# STM32G474xx register map
File version: 1.5
CPU: CM4 r0p1, little endian, MPU, FPU, 4 interrupt priority bits
Registers are 32-bit, read-write, reset 0x0 unless marked. A register's access mark holds for its fields unless they carry their own. Offsets are from the block's base; [hi:lo] are bit positions; lines under a group give offsets from that group; {n}, {i} and the like mark numbered series.

## ADC1 — Analog-to-Digital Converter
Base 0x50000000
Same registers: ADC2 0x50000100, ADC4 0x50000500
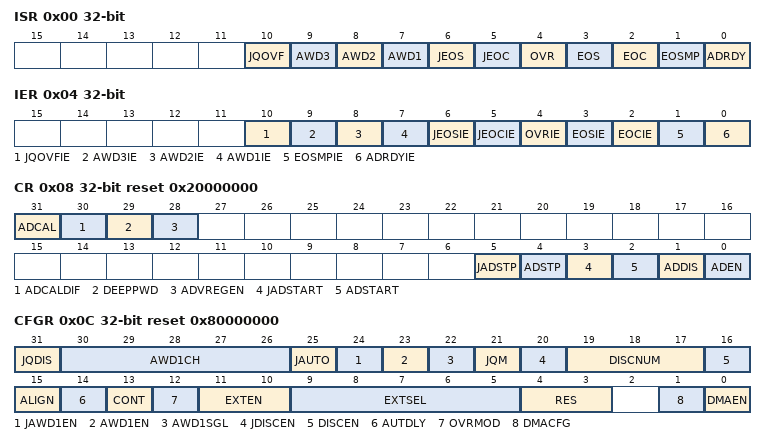
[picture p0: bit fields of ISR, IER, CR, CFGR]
0x00 ISR — interrupt and status register
  [10] JQOVF, [9] AWD3, [8] AWD2, [7] AWD1, [6] JEOS, [5] JEOC, [4] OVR, [3] EOS, [2] EOC, [1] EOSMP, [0] ADRDY
0x04 IER — interrupt enable register
  [10] JQOVFIE, [9] AWD3IE, [8] AWD2IE, [7] AWD1IE, [6] JEOSIE, [5] JEOCIE, [4] OVRIE, [3] EOSIE, [2] EOCIE, [1] EOSMPIE, [0] ADRDYIE
0x08 CR reset 0x20000000 — control register
  [31] ADCAL, [30] ADCALDIF, [29] DEEPPWD, [28] ADVREGEN, [5] JADSTP, [4] ADSTP, [3] JADSTART, [2] ADSTART, [1] ADDIS, [0] ADEN
0x0C CFGR reset 0x80000000 — configuration register
  [31] JQDIS — Injected Queue disable
  [30:26] AWD1CH — Analog watchdog 1 channel selection
  [25] JAUTO
  [24] JAWD1EN
  [23] AWD1EN
  [22] AWD1SGL
  [21] JQM
  [20] JDISCEN
  [19:17] DISCNUM
  [16] DISCEN
  [15] ALIGN
  [14] AUTDLY
  [13] CONT
  [12] OVRMOD
  [11:10] EXTEN
  [9:5] EXTSEL — External trigger selection for regular group
  [4:3] RES
  [1] DMACFG
  [0] DMAEN
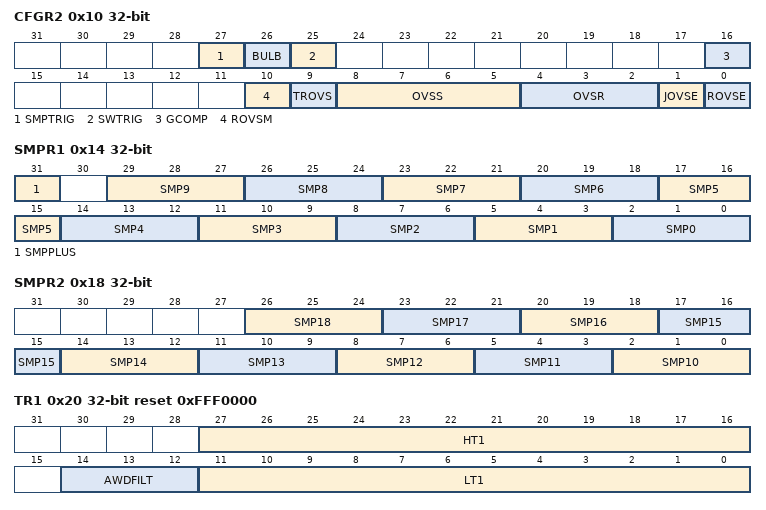
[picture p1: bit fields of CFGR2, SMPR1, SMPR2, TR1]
0x10 CFGR2 — configuration register
  [27] SMPTRIG
  [26] BULB
  [25] SWTRIG
  [16] GCOMP
  [10] ROVSM — EXTEN
  [9] TROVS — Triggered Regular Oversampling
  [8:5] OVSS — ALIGN
  [4:2] OVSR — RES
  [1] JOVSE — DMACFG
  [0] ROVSE — DMAEN
0x14 SMPR1 — sample time register 1
  [31] SMPPLUS — Addition of one clock cycle to the sampling time
  [3n+2:3n] SMP{n} (n=0..9)
0x18 SMPR2 — sample time register 2
  [3n-28:3n-30] SMP{n} (n=10..18)
0x20 TR1 reset 0xFFF0000 — watchdog threshold register 1
  [27:16] HT1, [14:12] AWDFILT, [11:0] LT1
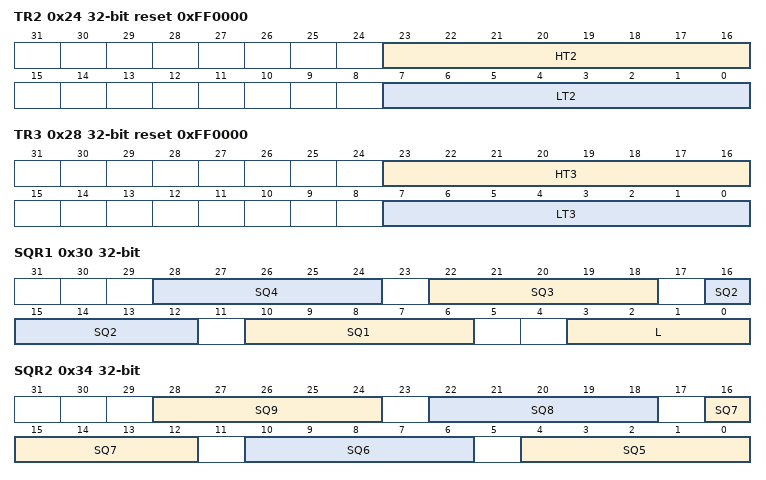
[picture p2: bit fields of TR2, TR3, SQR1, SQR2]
0x24 TR2 reset 0xFF0000 — watchdog threshold register
  [23:16] HT2, [7:0] LT2
0x28 TR3 reset 0xFF0000 — watchdog threshold register 3
  [23:16] HT3, [7:0] LT3
0x30 SQR1 — regular sequence register 1
  [6n+4:6n] SQ{n} (n=1..4)
  [3:0] L — Regular channel sequence length
0x34 SQR2 — regular sequence register 2
  [6n-26:6n-30] SQ{n} (n=5..9)
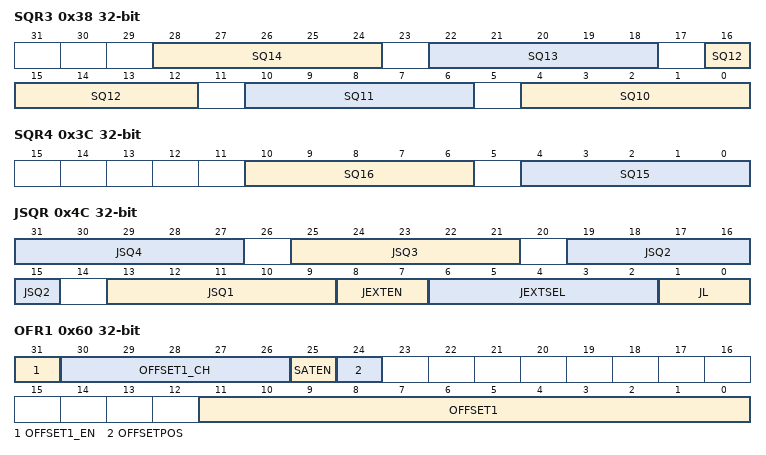
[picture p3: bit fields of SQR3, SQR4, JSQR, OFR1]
0x38 SQR3 — regular sequence register 3
  [6n-56:6n-60] SQ{n} (n=10..14)
0x3C SQR4 — regular sequence register 4
  [10:6] SQ16, [4:0] SQ15
0x40 DR ro — regular Data Register
  [15:0] RDATA — Regular Data converted
0x4C JSQR — injected sequence register
  [6n+7:6n+3] JSQ{n} (n=1..4), [8:7] JEXTEN, [6:2] JEXTSEL, [1:0] JL
0x60 OFR1 — offset register 1
  [31] OFFSET1_EN, [30:26] OFFSET1_CH, [25] SATEN, [24] OFFSETPOS, [11:0] OFFSET1
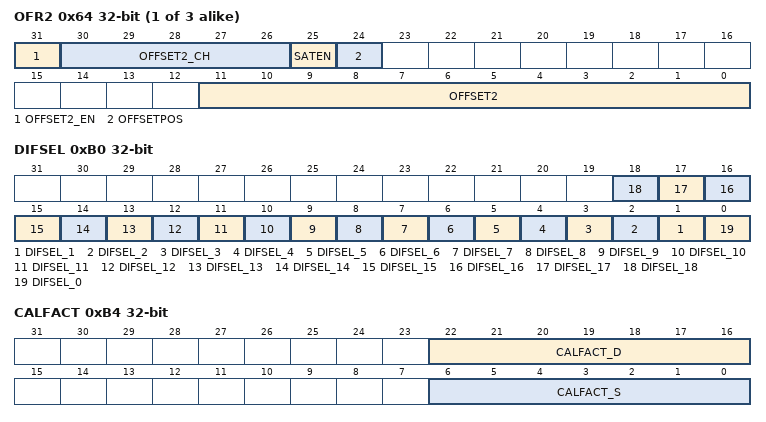
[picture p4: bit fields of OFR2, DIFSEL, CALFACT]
{0x5C+4i} OFR{i} (i=2..4) — offset register {i}
  [31] OFFSET{i}_EN — OFFSET1_EN
  [30:26] OFFSET{i}_CH — OFFSET1_CH
  [25] SATEN
  [24] OFFSETPOS
  [11:0] OFFSET{i} — OFFSET1
{0x7C+4i} JDR{i} ro (i=1..4) — injected data register {i}
  [15:0] JDATA{i}
0xA0 AWD2CR — Analog Watchdog 2 Configuration Register
  [18:0] AWD2CH
0xA4 AWD3CR — Analog Watchdog 3 Configuration Register
  [18:0] AWD3CH
0xB0 DIFSEL access per field — Differential Mode Selection Register 2
  [n] DIFSEL_{n} rw (n=1..18) — Differential mode for channels {n}
  [0] DIFSEL_0 ro — Differential mode for channels 0
0xB4 CALFACT — Calibration Factors
  [22:16] CALFACT_D, [6:0] CALFACT_S
0xC0 GCOMP — Gain compensation Register
  [13:0] GCOMPCOEFF

## ADC3 — Analog-to-Digital Converter
Base 0x50000400
Same registers: ADC5 0x50000600
Registers as ADC1; these are added or differ:
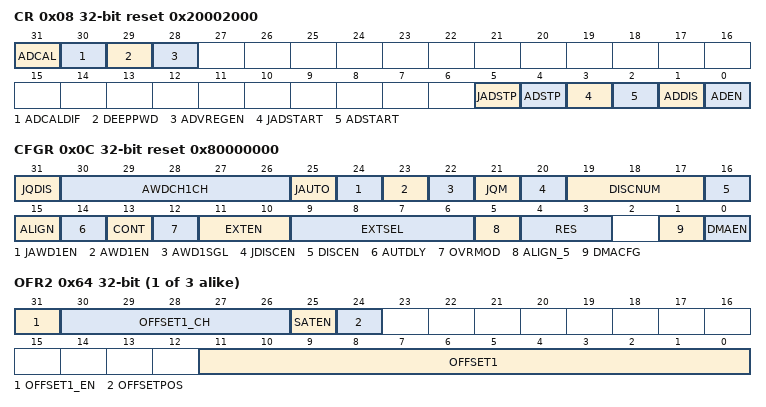
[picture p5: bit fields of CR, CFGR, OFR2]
0x08 CR reset 0x20002000 — control register
  [31] ADCAL, [30] ADCALDIF, [29] DEEPPWD, [28] ADVREGEN, [5] JADSTP, [4] ADSTP, [3] JADSTART, [2] ADSTART, [1] ADDIS, [0] ADEN
0x0C CFGR reset 0x80000000 — configuration register
  [31] JQDIS — Injected Queue disable
  [30:26] AWDCH1CH
  [25] JAUTO
  [24] JAWD1EN
  [23] AWD1EN
  [22] AWD1SGL
  [21] JQM
  [20] JDISCEN
  [19:17] DISCNUM
  [16] DISCEN
  [15] ALIGN
  [14] AUTDLY
  [13] CONT
  [12] OVRMOD
  [11:10] EXTEN
  [9:6] EXTSEL
  [5] ALIGN_5
  [4:3] RES
  [1] DMACFG
  [0] DMAEN
{0x5C+4i} OFR{i} (i=2..4) — offset register {i}
  [31] OFFSET1_EN, [30:26] OFFSET1_CH, [25] SATEN, [24] OFFSETPOS, [11:0] OFFSET1
